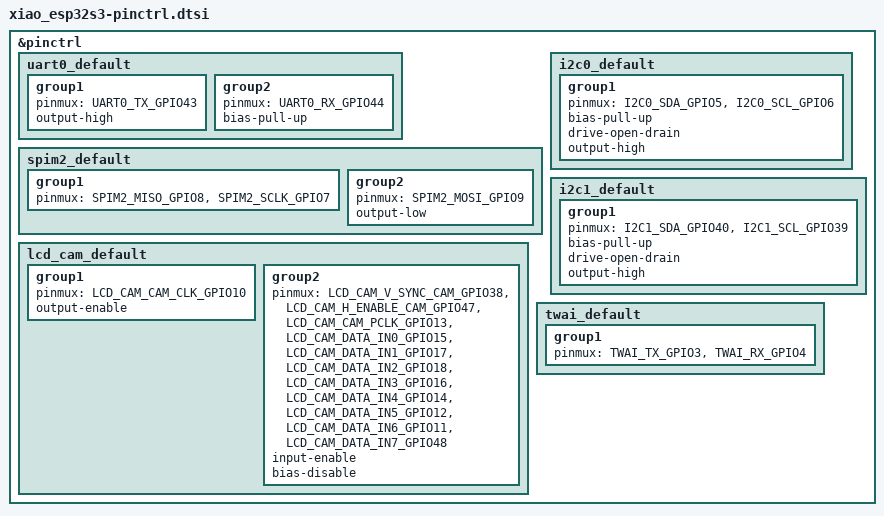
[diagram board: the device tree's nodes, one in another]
/*
 * Copyright 2022 Google LLC
 *
 * SPDX-License-Identifier: Apache-2.0
 */

#include <zephyr/dt-bindings/pinctrl/esp-pinctrl-common.h>
#include <dt-bindings/pinctrl/esp32s3-pinctrl.h>
#include <zephyr/dt-bindings/pinctrl/esp32s3-gpio-sigmap.h>

&pinctrl {
	uart0_default: uart0_default {
		group1 {
			pinmux = <UART0_TX_GPIO43>;
			output-high;
		};

		group2 {
			pinmux = <UART0_RX_GPIO44>;
			bias-pull-up;
		};
	};

	spim2_default: spim2_default {
		group1 {
			pinmux = <SPIM2_MISO_GPIO8>,
				 <SPIM2_SCLK_GPIO7>;
		};

		group2 {
			pinmux = <SPIM2_MOSI_GPIO9>;
			output-low;
		};
	};

	i2c0_default: i2c0_default {
		group1 {
			pinmux = <I2C0_SDA_GPIO5>,
				 <I2C0_SCL_GPIO6>;
			bias-pull-up;
			drive-open-drain;
			output-high;
		};
	};

	i2c1_default: i2c1_default {
		group1 {
			pinmux = <I2C1_SDA_GPIO40>,
				 <I2C1_SCL_GPIO39>;
			bias-pull-up;
			drive-open-drain;
			output-high;
		};
	};

	lcd_cam_default: lcd_cam_default {
		group1 {
			pinmux = <LCD_CAM_CAM_CLK_GPIO10>;
			output-enable;
		};

		group2 {
			pinmux = <LCD_CAM_V_SYNC_CAM_GPIO38>,
				 <LCD_CAM_H_ENABLE_CAM_GPIO47>,
				 <LCD_CAM_CAM_PCLK_GPIO13>,
				 <LCD_CAM_DATA_IN0_GPIO15>,
				 <LCD_CAM_DATA_IN1_GPIO17>,
				 <LCD_CAM_DATA_IN2_GPIO18>,
				 <LCD_CAM_DATA_IN3_GPIO16>,
				 <LCD_CAM_DATA_IN4_GPIO14>,
				 <LCD_CAM_DATA_IN5_GPIO12>,
				 <LCD_CAM_DATA_IN6_GPIO11>,
				 <LCD_CAM_DATA_IN7_GPIO48>;
			input-enable;
			bias-disable;
		};
	};

	twai_default: twai_default {
		group1 {
			pinmux = <TWAI_TX_GPIO3>,
				 <TWAI_RX_GPIO4>;
		};
	};
};
